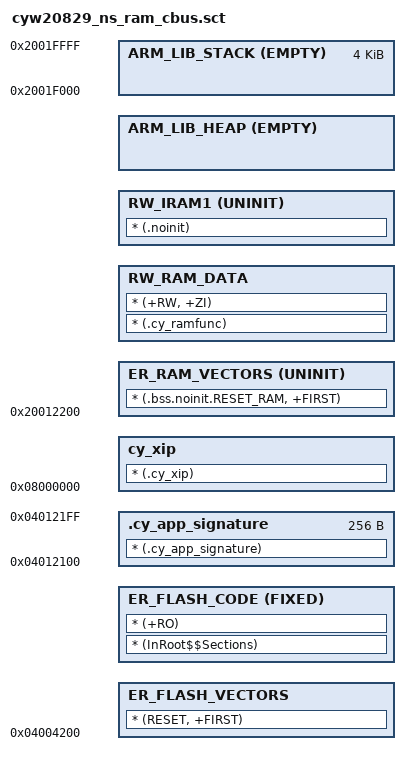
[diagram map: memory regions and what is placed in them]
#! armclang -E --target=arm-arm-none-eabi -x c -mcpu=cortex-m33
; The first line specifies a preprocessor command that the linker invokes
; to pass a scatter file through a C preprocessor.

;*******************************************************************************
;* \file cyw20829_ns.sct
;* \version 1.0.0
;*
;* Linker file for the ARMCC.
;*
;* The main purpose of the linker script is to describe how the sections in the
;* input files should be mapped into the output file, and to control the memory
;* layout of the output file.
;*
;* \note The entry point location is fixed and starts at 0x10000000. The valid
;* application image should be placed there.
;*
;* \note The linker files included with the PDL template projects must be
;* generic and handle all common use cases. Your project may not use every
;* section defined in the linker files. In that case you may see the warnings
;* during the build process: L6314W (no section matches pattern) and/or L6329W
;* (pattern only matches removed unused sections). In your project, you can
;* suppress the warning by passing the "--diag_suppress=L6314W,L6329W" option to
;* the linker, simply comment out or remove the relevant code in the linker
;* file.
;*
;*******************************************************************************
;* \copyright
;* Copyright 2016-2020 Cypress Semiconductor Corporation
;* SPDX-License-Identifier: Apache-2.0
;*
;* Licensed under the Apache License, Version 2.0 (the "License");
;* you may not use this file except in compliance with the License.
;* You may obtain a copy of the License at
;*
;*     http://www.apache.org/licenses/LICENSE-2.0
;*
;* Unless required by applicable law or agreed to in writing, software
;* distributed under the License is distributed on an "AS IS" BASIS,
;* WITHOUT WARRANTIES OR CONDITIONS OF ANY KIND, either express or implied.
;* See the License for the specific language governing permissions and
;* limitations under the License.
;******************************************************************************/

; The defines below describe the location and size of blocks of memory in the target.
; Use these defines to specify the memory regions available for allocation.

; The following defines control RAM and flash memory allocation for the CM33 core.
; RAM

#define CODE_ROM_NS_CBUS_START 0x00000000
#define CODE_ROM_NS_CBUS_SIZE 0x00010000
#define CODE_SRAM0_NS_CBUS_START 0x04004200
#define CODE_SRAM0_NS_CBUS_SIZE 0x0000E000
#define CODE_XIP_NS_CBUS_START 0x08000000
#define CODE_XIP_NS_CBUS_SIZE 0x08000000

#define DATA_ROM_NS_SAHB_START 0x00000000
#define DATA_ROM_NS_SAHB_SIZE  0x00000000
#define BSS_ROM_NS_SAHB_START 0x00000000
#define BSS_ROM_NS_SAHB_SIZE 0x00000000
#define DATA_SRAM0_NS_SAHB_START 0x20012200
#define DATA_SRAM0_NS_SAHB_SIZE  0x0000DE00
#define BSS_SRAM0_NS_SAHB_START 0x20000000
#define BSS_SRAM0_NS_SAHB_SIZE 0x00000000
#define DATA_XIP_NS_SAHB_START 0x60000000
#define DATA_XIP_NS_SAHB_SIZE  0x00000000
#define BSS_XIP_NS_SAHB_START 0x60000000
#define BSS_XIP_NS_SAHB_SIZE 0x00000000


/*
#define RAM_START               0x20004200
#define RAM_SIZE                0x0001BE00
*/
#define RAM_START               DATA_SRAM0_NS_SAHB_START
#define RAM_SIZE                DATA_SRAM0_NS_SAHB_SIZE

; Flash
/*
#define FLASH_START             0x60000000
#define FLASH_SIZE              0x00010000
*/

#define FLASH_START             CODE_SRAM0_NS_CBUS_START
#define FLASH_SIZE              CODE_SRAM0_NS_CBUS_SIZE

; The size of the stack section at the end of CM33 SRAM
#define STACK_SIZE              0x00001000

; The size of the MCU boot header area at the start of FLASH
#define BOOT_HEADER_SIZE        0x00000000

; The following defines describe device specific memory regions and must not be changed.

; External memory
#define XIP_START               CODE_XIP_NS_CBUS_START
#define XIP_SIZE                CODE_XIP_NS_CBUS_SIZE


; Cortex-M33 application flash area
LR_IROM1 (FLASH_START + BOOT_HEADER_SIZE) (FLASH_SIZE - BOOT_HEADER_SIZE)
{
    ER_FLASH_VECTORS +0
    {
        * (RESET, +FIRST)
    }

    ER_FLASH_CODE +0 FIXED
    {
        * (InRoot$$Sections)
        * (+RO)
    }

    ER_RAM_VECTORS RAM_START UNINIT
    {
        * (.bss.noinit.RESET_RAM, +FIRST)
    }

    RW_RAM_DATA +0
    {
        * (.cy_ramfunc)
        * (+RW, +ZI)
    }

    ; Place variables in the section that should not be initialized during the
    ; device startup.
    RW_IRAM1 +0 UNINIT
    {
        * (.noinit)
    }

    ; Application heap area (HEAP)
    ARM_LIB_HEAP  +0 ALIGN 8 EMPTY ((RAM_START+RAM_SIZE)-AlignExpr(ImageLimit(RW_IRAM1), 8)-STACK_SIZE)
    {
    }

    ; Stack region growing down
    ARM_LIB_STACK (RAM_START+RAM_SIZE) ALIGN 32 EMPTY -STACK_SIZE
    {
    }

    ; Used for the digital signature of the secure application and the
    ; Bootloader SDK application. The size of the section depends on the required
    ; data size.
    .cy_app_signature (FLASH_START + FLASH_SIZE - 256) 256
    {
        * (.cy_app_signature)
    }
}


; Places the code in the Execute in Place (XIP) section. See the smif driver documentation for details.
LR_EROM XIP_START XIP_SIZE
{
    cy_xip +0
    {
        * (.cy_xip)
    }
}


/* [] END OF FILE */
